# DISPC_VID1 register map
Vendor: Texas Instruments
Peripheral module from a debugger description file (folder DM50x).
Registers are 32-bit, access per field, reset 0x0 unless marked. A register's access mark holds for its fields unless they carry their own. Offsets are as the file gives them; lines under a group give offsets from that group; [hi:lo] are bit positions; {n}, {i} and the like mark numbered series; 'fields as' and 'values as' point back to an identical list; <NAME> marks a mode.

## DISPC_VID1
0x00 DISPC_VID_ACCUH_j_0 — The register configures the resize accumulator init values for horizontal up/down-sampling of the video window (DISPC_VIDx_ACCU__0 DISPC_VIDx_ACCU__1 for ping-pong mechanism with external trigger, based on the field polarity) It is used for ARGB and Y setting. Shadow register.
  [23:0] HORIZONTALACCU rw — Horizontal initialization accu signed value.
0x04 DISPC_VID_ACCUH_j_1 — The register configures the resize accumulator init values for horizontal up/down-sampling of the video window (DISPC_VIDx_ACCU__0 DISPC_VIDx_ACCU__1 for ping-pong mechanism with external trigger, based on the field polarity) It is used for ARGB and Y setting. Shadow register.
  fields as DISPC_VID_ACCUH_j_0
0x08 DISPC_VID_ACCUH2_j_0 — The register configures the resize accumulator init value for horizontal up/down-sampling of the video window (DISPC_VID#n_ACCU2__0 DISPC_VID#n_ACCU2__1 for ping-pong mechanism with external trigger, based on the field polarity) It is used for Cb and Cr setting. It is used only when the pixel format at the input of the filter is one of the YUV formats. If the pixel format at the input of the filter is ARGB (all ARGB, RGB, RGBA are converted to ARGB32-8888 by the color space conversion before going to the filter is the color space conversion is done before the filter). When the register is not used by the HW, any value can be used for the bit-fields. Shadow register.
  [23:0] HORIZONTALACCU rw — Horizontal initialization accu signed value
0x0C DISPC_VID_ACCUH2_j_1 — The register configures the resize accumulator init value for horizontal up/down-sampling of the video window (DISPC_VID#n_ACCU2__0 DISPC_VID#n_ACCU2__1 for ping-pong mechanism with external trigger, based on the field polarity) It is used for Cb and Cr setting. It is used only when the pixel format at the input of the filter is one of the YUV formats. If the pixel format at the input of the filter is ARGB (all ARGB, RGB, RGBA are converted to ARGB32-8888 by the color space conversion before going to the filter is the color space conversion is done before the filter). When the register is not used by the HW, any value can be used for the bit-fields. Shadow register.
  fields as DISPC_VID_ACCUH2_j_0
0x10 DISPC_VID_ACCUV_j_0 — The register configures the resize accumulator init values for horizontal and vertical up/down-sampling of the video window (DISPC_VIDx_ACCU__0 DISPC_VIDx_ACCU__1 for ping-pong mechanism with external trigger, based on the field polarity) It is used for ARGB and Y setting. Shadow register.
  [23:0] VERTICALACCU rw — Vertical initialization accu signed value.
0x14 DISPC_VID_ACCUV_j_1 — The register configures the resize accumulator init values for horizontal and vertical up/down-sampling of the video window (DISPC_VIDx_ACCU__0 DISPC_VIDx_ACCU__1 for ping-pong mechanism with external trigger, based on the field polarity) It is used for ARGB and Y setting. Shadow register.
  [23:0] VERTICALACCU rw — Vertical initialization accu signed value.
0x18 DISPC_VID_ACCUV2_j_0 — The register configures the resize accumulator init value for vertical up/down-sampling of the video window (DISPC_VID1_ACCU2__0 DISPC_VID1_ACCU2__1 for ping-pong mechanism with external trigger, based on the field polarity) It is used for Cb and Cr setting. It is used only when the pixel format at the input of the filter is one of the YUV formats. If the pixel format at the input of the filter is ARGB (all ARGB, RGB, RGBA are converted to ARGB32-8888 by the color space conversion before going to the filter is the color space conversion is done before the filter). When the register is not used by the HW, any value can be used for the bit-fields. Shadow register.
  [23:0] VERTICALACCU rw — Vertical initialization accu signed value.
0x1C DISPC_VID_ACCUV2_j_1 — The register configures the resize accumulator init value for vertical up/down-sampling of the video window (DISPC_VID1_ACCU2__0 DISPC_VID1_ACCU2__1 for ping-pong mechanism with external trigger, based on the field polarity) It is used for Cb and Cr setting. It is used only when the pixel format at the input of the filter is one of the YUV formats. If the pixel format at the input of the filter is ARGB (all ARGB, RGB, RGBA are converted to ARGB32-8888 by the color space conversion before going to the filter is the color space conversion is done before the filter). When the register is not used by the HW, any value can be used for the bit-fields. Shadow register.
  [23:0] VERTICALACCU rw — Vertical initialization accu signed value.
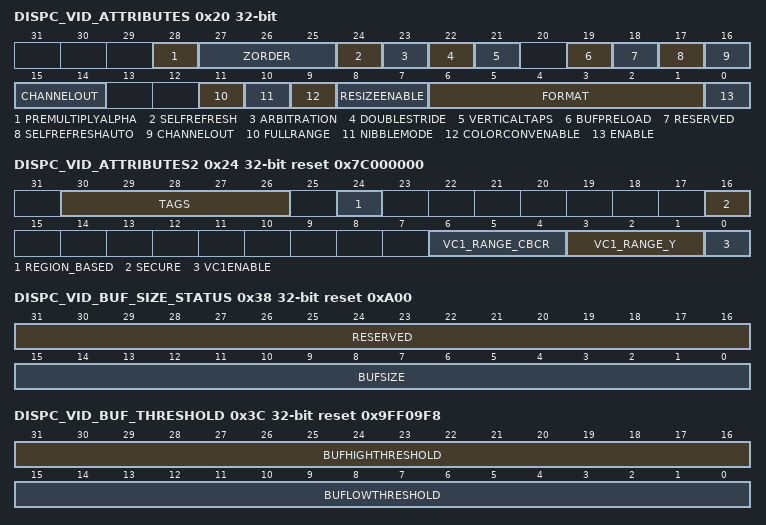
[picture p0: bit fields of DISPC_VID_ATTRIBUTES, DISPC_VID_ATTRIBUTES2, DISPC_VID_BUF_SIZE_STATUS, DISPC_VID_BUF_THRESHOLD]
0x20 DISPC_VID_ATTRIBUTES — The register configures the attributes of the video window. Shadow register.
  [28] PREMULTIPLYALPHA rw — The field configures the DISPC VID1 to process incoming data as premultiplied alpha data or non premultiplied alpha data. Default setting is non premultiplied alpha data.
    0=NONPREMULTIPLIEDALPHA (Non premultiplyalpha data color component); 1=PREMULTIPLIEDALPHA (Premultiplyalpha data color component)
  [27:25] ZORDER rw — Z-Order defining the priority of the layer compared to others when overlaying. It is SW responsibility to ensure that each layer connected to the same overlay manager has a different z-order value.
    1=Z-order 1: layer above layer with z-order value of 0 and below layers with z-order values of 2 and 3; 0=Z-order 0: layer above solid background color and below layer with higher Z-order values; 2=Z-order 2: layer above layers with z-order value of 0 and 1 and below layer with z-order value of 3; 4=Z-order 4: layer above layers with z-order value of 0, 1, 2 and 3 and below layer with z-order value of 5; 5=Z-order 5: layer above all the other layers except cursor; 3=Z-order 3: layer above layers with z-order value of 0, 1 and 2 and below layer with z-order value of 4
  [24] SELFREFRESH rw — Enables the self refresh of the video window from its own DMA buffer only.
    0=SELFREFRESHDIS (The video pipeline accesses the interconnect to fetch data from the system memory.); 1=SELFREFRESHENB (The video pipeline does not need anymore to fetch data from memory. Only the DMA buffer associated with the video1 is used. It takes effect after the frame has been loaded in the DMA buffer.)
  [23] ARBITRATION rw — Determines the priority of the video pipeline. The video pipeline is one of the high priority pipeline. The arbitration gives always the priority first to the high priority pipelines using round-robin between them. When there is only normal priority pipelines sending requests, the round-robin applies between them.
    0=NORMALPRIO (The video pipeline is one of the normal priority pipeline.); 1=HIGHPRIO (The video pipeline is one of the high priority pipeline.)
  [22] DOUBLESTRIDE rw — Determines if the stride for CbCr buffer is the 1x or 2x of the Y buffer stride. It is only used in case of YUV420 and 2D access
    0=INITIAL (The CbCr stride value is equal to the Y stride.); 1=DOUBLE (The CbCr stride value is double to the Y stride.)
  [21] VERTICALTAPS rw — Video Vertical Resize Tap Number. The vertial poly-phase filter can be configured in 3-tap or 5-tap configuration. According to the number of taps, the maximum input picture width is double while using 3-tap compared to 5-tap.
    0=TAPS3 (3 taps are used for the vertical filtering logic. The 2 other taps are not used. The associated bit-fields for the 2 other taps coefficients do not need to be initialized.); 1=TAPS5 (5 taps are used for the vertical filtering logic.)
  [19] BUFPRELOAD rw — Video Preload Value
    0=DEFVAL (H/W prefetches pixels up to the preload value defined in the preload register); 1=HIGHTHRES (H/W prefetches pixels up to high threshold value)
  [18] RESERVED ro — Write 0's for future compatibility. Reads return 0.
  [17] SELFREFRESHAUTO rw — Automatic self refresh mode
    0=SELFREFRESHAUTODIS (The transition from SELFREFRESH <disabled> to <enabled> is controlled by SW.); 1=SELFREFRESHAUTOEN (The transition from SELFREFRESH <disabled> to <enabled> is controlled only by HW.)
  [16:14] CHANNELOUT rw — Video Channel Out configuration wr: immediate
    0=VP1SEL (OVR1 (VP1)); 1=VP1SEL (OVR2); 4=WBSEL
  [11] FULLRANGE rw — Color Space Conversion full range setting.
    0=LIMRANGE (Limited range selected: 16 subtracted from Y before color space conversion); 1=FULLRANGE (Full range selected: Y is not modified before the color space conversion)
  [10] NIBBLEMODE rw — Video Nibble mode (only for 1-, 2- and 4-bpp)
    0=NIBBLEMODEDIS (Nibble mode is disabled); 1=NIBBLEMODEEN (Nibble mode is enabled)
  [9] COLORCONVENABLE rw — Enable the color space conversion. The HW does not enable/disable the conversion based on the pixel format. The bit-field shall be reset when the format is not YUV.
    0=COLSPCDIS (Disable Color Space Conversion YUV to RGB); 1=COLSPCENB (Enable Color Space Conversion YUV to RGB)
  [8:7] RESIZEENABLE rw — Video Resize Enable
    0=RESIZEPROC (Disable both horizontal and vertical resize processing); 1=HRESIZE (Enable the horizontal resize processing); 3=HVRESIZE (Enable both horizontal and vertical resize processing); 2=VRESIZE (Enable the vertical resize processing)
  [6:1] FORMAT rw — Video Format. It defines the pixel format when fetching the video frame buffer.
    9=RGBA32_8888; 21=BITMAP8 (BITMAP8 (CLUT is required)); 8=ABGR32_8888; 5=ARGB16_1555; 46=XRGB32_2101010; 2=RGBA16_4444; 4=BGR16_565; 1=ABGR16_4444; 63=UYVY (UYVY 4:2:2 co-sited); 40=XBGR32_8888; 0=ARGB16_4444; 62=YUV2 (YUV2 4:2:2 co-sited); 11=RGB24P_888 (RGB24-888 (24-bit container)); 61=NV12 (NV12/N21 4:2:0 2 buffers (Y + UV)); 32=XRGB16_4444 (xRGB12-4444); 3=RGB16_565; 23=BGR565A8; 48=XRGB64_16161616; 49=RGBX64_16161616; 17=RGBA64_16161616; 6=ABGR16_1555; 47=XBGR32_2101010; 10=BGRA32_8888; 38=XBGR16_1555; 16=ARGB64_16161616; 33=XBGR16_4444; 37=XRGB16_1555; 18=BITMAP1 (BITMAP1 (CLUT is required)); 19=BITMAP2 (BITMAP2 (CLUT is required)); 20=BITMAP4 (BITMAP4 (CLUT is required)); 14=ARGB32_2101010; 22=RGB565A8; 42=BGRX32_8888; 7=ARGB32_8888; 39=XRGB32_8888 (xRGB32-8888 (32-bit container)); 41=RGBX32_8888 (RGBx32-8888 (24-bit RGB aligned on MSB of the 32-bit container)); 15=ABGR32_2101010; 34=RGBX16_4444
  [0] ENABLE rw — Video pipeline Enable
    0=VIDEODIS (Video disabled (video pipeline inactive and window not present)); 1=VIDEOENB (Video enabled (video pipeline active and window present on the screen))
0x24 DISPC_VID_ATTRIBUTES2 reset 0x7C000000 — The register configures the attributes of the video window. Shadow register.
  [30:26] TAGS rw — Number of OCP TAGS to be used for the pipeline (from 1 to 32)
  [24] REGION_BASED rw — Enable region-based mechanism
    0=DISABLE; 1=ENABLE
  [16] SECURE rw — OCP requests corresponds to pipeline data are secure/unsecure. The bit-field can be modified only by secure transaction using MReqSecure qualifier.
  [6:4] VC1_RANGE_CBCR rw — Defines the VC1 range value for the CbCr component from 0 to 7.
  [3:1] VC1_RANGE_Y rw — Defines the VC1 range value for the Y component from 0 to 7.
  [0] VC1ENABLE rw — Enable/disable the VC1 range mapping processing. The bit-field is ignored if the format is not one of the supported YUV formats.
    0=VC1DIS (VC1 range mapping disabled); 1=VC1ENB (VC1 range mapping enabled)
0x28 DISPC_VID_BA_j_0 rw — The register configures the base address of the video buffer for the video window (DISPC_VID1_BA__0 DISPC_VID1_BA__1 for ping-pong mechanism with external trigger, based on the field polarity otherwise only DISPC_VID1_BA__0 is used). Shadow register.
  [31:0] BA — Video base address When decompression is enabled bit[5:0] shall be set to 0. Base address of the video buffer (aligned on pixel size boundary except in case of RGB24 packed format, 4-pixel alignment is required; in case of YUV422, 2-pixel alignment is required, and YUV420, byte alignment is supported)). It case of YUV 4:2:0 format, it indicates the base address of the Y buffer. When the TILER is addressed, the bits: [28:27] = 0x0 for 8-bit tiled [28:27] = 0x1 for 16-bit tiled [28:27] = 0x2 for 32-bit tiled [28:27] = 0x3 for page mode [31:29] = 0x0 for 0-degree view [31:29] = 0x1 for 180-degree view + mirroring [31:29] = 0x2 for 0-degree view + mirroring [31:29] = 0x3 for 180-degree view [31:29] = 0x4 for 270-degree view + mirroring [31:29] = 0x5 for 270-degree view [31:29] = 0x6 for 90-degree view [31:29] = 0x7 for 90-degree view + mirroring Otherwise the bits indicated the corresponding bit address to access the SDRAM.
0x2C DISPC_VID_BA_j_1 rw — The register configures the base address of the video buffer for the video window (DISPC_VID1_BA__0 DISPC_VID1_BA__1 for ping-pong mechanism with external trigger, based on the field polarity otherwise only DISPC_VID1_BA__0 is used). Shadow register.
  fields as DISPC_VID_BA_j_0
0x30 DISPC_VID_BA_UV_j_0 rw — The register configures the base address of the UV buffer for the video window. (DISPC_VID1_BA_UV__0 DISPC_VID1_BA_UV__1 for ping-pong mechanism with external trigger, based on the field polarity otherwise only DISPC_VID1_BA_UV__0 is used)). The register is also used to configure the RGB plane BA for RGB565A8 format Shadow register.
  [31:0] BA — Video base address alinged on 16-bit boundary Base address of the UV video buffer used only in case of YUV420-NV12 When the TILER is addressed, the bits: [28:27] = 0x0 for 8-bit tiled [28:27] = 0x1 for 16-bit tiled [28:27] = 0x2 for 32-bit tiled [28:27] = 0x3 for page mode [31:29] = 0x0 for 0-degree view [31:29] = 0x1 for 180-degree view + mirroring [31:29] = 0x2 for 0-degree view + mirroring [31:29] = 0x3 for 180-degree view [31:29] = 0x4 for 270-degree view + mirroring [31:29] = 0x5 for 270-degree view [31:29] = 0x6 for 90-degree view [31:29] = 0x7 for 90-degree view + mirroring Otherwise the bits indicated the corresponding bit address to access the SDRAM.
0x34 DISPC_VID_BA_UV_j_1 rw — The register configures the base address of the UV buffer for the video window. (DISPC_VID1_BA_UV__0 DISPC_VID1_BA_UV__1 for ping-pong mechanism with external trigger, based on the field polarity otherwise only DISPC_VID1_BA_UV__0 is used)). The register is also used to configure the RGB plane BA for RGB565A8 format Shadow register.
  fields as DISPC_VID_BA_UV_j_0
0x38 DISPC_VID_BUF_SIZE_STATUS ro reset 0xA00 — The register defines the Video buffer size for the video pipeline.
  [31:16] RESERVED — Write 0's for future compatibility. Reads return 0
  [15:0] BUFSIZE — Video DMA buffer Size in number of 128-bits
0x3C DISPC_VID_BUF_THRESHOLD rw reset 0x9FF09F8 — The register configures the video buffer associated with the video pipeline. Shadow register.
  [31:16] BUFHIGHTHRESHOLD — Video DMA buffer High Threshold Number of 128-bits defining the threshold value.
  [15:0] BUFLOWTHRESHOLD — DMA buffer High Threshold Number of 128-bits defining the threshold value.
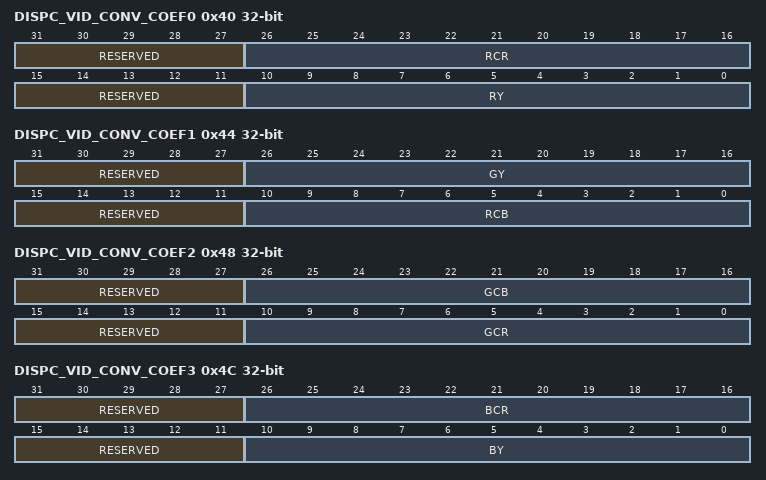
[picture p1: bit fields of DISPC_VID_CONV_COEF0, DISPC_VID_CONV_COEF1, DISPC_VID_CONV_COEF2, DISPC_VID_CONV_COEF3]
0x40 DISPC_VID_CONV_COEF0 — The register configures the color space conversion matrix coefficients for the video pipeline. Shadow register.
  [31:27] RESERVED ro — Write 0's for future compatibility. Reads return 0
  [26:16] RCR rw — RCr Coefficient Encoded signed value (from -1024 to 1023).
  [15:11] RESERVED ro — Write 0's for future compatibility. Reads return 0
  [10:0] RY rw — RY Coefficient Encoded signed value (from -1024 to 1023).
0x44 DISPC_VID_CONV_COEF1 — The register configures the color space conversion matrix coefficients for the video pipeline. Shadow register.
  [31:27] RESERVED ro — Write 0's for future compatibility. Reads return 0
  [26:16] GY rw — GY Coefficient Encoded signed value (from -1024 to 1023).
  [15:11] RESERVED ro — Write 0's for future compatibility. Reads return 0
  [10:0] RCB rw — RCb Coefficient Encoded signed value (from -1024 to 1023).
0x48 DISPC_VID_CONV_COEF2 — The register configures the color space conversion matrix coefficients for the video pipeline. Shadow register.
  [31:27] RESERVED ro — Write 0's for future compatibility. Reads return 0
  [26:16] GCB rw — GCb Coefficient Encoded signed value (from -1024 to 1023).
  [15:11] RESERVED ro — Write 0's for future compatibility. Reads return 0
  [10:0] GCR rw — GCr Coefficient Encoded signed value (from -1024 to 1023).
0x4C DISPC_VID_CONV_COEF3 — The register configures the color space conversion matrix coefficients for the video pipeline. Shadow register.
  [31:27] RESERVED ro — Write 0's for future compatibility. Reads return 0
  [26:16] BCR rw — BCr coefficient Encoded signed value (from -1024 to 1023).
  [15:11] RESERVED ro — Write 0's for future compatibility. Reads return 0
  [10:0] BY rw — BY coefficient Encoded signed value (from -1024 to 1023).
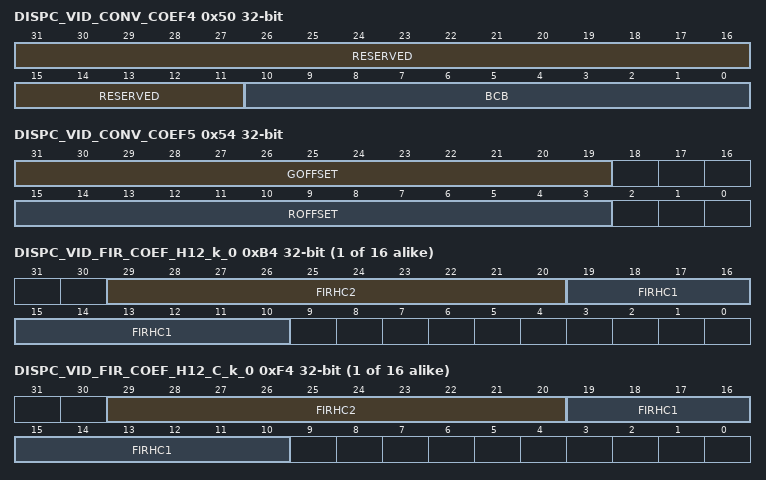
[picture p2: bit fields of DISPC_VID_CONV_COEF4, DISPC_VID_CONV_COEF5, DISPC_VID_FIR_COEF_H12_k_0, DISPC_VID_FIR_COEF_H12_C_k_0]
0x50 DISPC_VID_CONV_COEF4 — The register configures the color space conversion matrix coefficients for the video pipeline. Shadow register.
  [31:11] RESERVED ro — Write 0's for future compatibility. Reads return 0
  [10:0] BCB rw — BCb Coefficient Encoded signed value (from -1024 to 1023).
0x54 DISPC_VID_CONV_COEF5 — The register configures the color space conversion matrix coefficients for the video pipeline. Shadow register.
  [31:19] GOFFSET rw — G offset Encoded signed value (from -4096 to 4095).
  [15:3] ROFFSET rw — R offset Encoded signed value (from -4096 to 4095).
0x58 DISPC_VID_CONV_COEF6 — The register configures the color space conversion matrix coefficients for the video pipeline. Shadow register.
  [15:3] BOFFSET rw — B offset Encoded signed value (from -4096 to 4095).
0x5C DISPC_VID_FIRH reset 0x200000 — The register configures the resize factor for horizontal up/down-sampling of the video window. It is used for ARGB and Y setting. Shadow register.
  [23:0] FIRHINC rw — Horizontal increment of the up/down-sampling filter. The value 0 is invalid.
0x60 DISPC_VID_FIRH2 reset 0x200000 — The register configures the resize factor for horizontal up/down-sampling of the video window. It is used for Crb and Cr setting. It is used only when the pixel format at the input of the filter is one of the YUV formats. If the pixel format at the input of the filter is ARGB (all ARGB, RGB, RGBA are converted to ARGB32-8888 by the color space conversion before going to the filter is the color space conversion is done before the filter). When the register is not used by the HW, any value can be used for the bit-fields. Shadow register.
  [23:0] FIRHINC rw — Horizontal increment of the up/down-sampling filter for Cb and Cr. The value 0 is invalid.
0x64 DISPC_VID_FIRV reset 0x200000 — The register configures the resize factor for vertical up/down-sampling of the video window. It is used for ARGB and Y setting. Shadow register.
  [23:0] FIRVINC rw — Vertical increment of the up/down-sampling filter. The value 0 is invalid.
0x68 DISPC_VID_FIRV2 reset 0x200000 — The register configures the resize factor for vertical up/down-sampling of the video window. It is used for Crb and Cr setting. It is used only when the pixel format at the input of the filter is one of the YUV formats. If the pixel format at the input of the filter is ARGB (all ARGB, RGB, RGBA are converted to ARGB32-8888 by the color space conversion before going to the filter is the color space conversion is done before the filter). When the register is not used by the HW, any value can be used for the bit-fields. Shadow register.
  [23:0] FIRVINC rw — Vertical increment of the up/down-sampling filter for Cb and Cr. The value 0 is invalid.
{0x6C+4i} DISPC_VID_FIR_COEF_H0_i_{i} (i=0..8) — The bank of registers configure the up/down-scaling coefficients for the horizontal resize of the video picture associated with the video window for the 16 phases It is used for ARGB and Y setting. Shadow register.
  [9:0] FIRHC0 rw — Unsigned coefficient C0 for the horizontal up/down-scaling with the phase n
{0x90+4i} DISPC_VID_FIR_COEF_H0_C_i_{i} (i=0..8) — The bank of registers configure the up/down-scaling coefficients for the horizontal resize of the video picture associated with the video window for the phases from 0 to 15. It is used for Crb and Cr setting. It is used only when the pixel format at the input of the filter is one of the YUV formats. If the pixel format at the input of the filter is ARGB (all ARGB, RGB, RGBA are converted to ARGB32-8888 by the color space conversion before going to the filter is the color space conversion is done before the filter). When the register is not used by the HW, any value can be used for the bit-fields. Shadow register.
  fields as DISPC_VID_FIR_COEF_H0_i_0
{0xB4+4i} DISPC_VID_FIR_COEF_H12_k_{i} (i=0..15) — The bank of registers configure the up/down-scaling coefficients for the horizontal resize of the video picture associated with the video window for the 16 phases It is used for ARGB and Y setting. Shadow register.
  [29:20] FIRHC2 rw — Signed coefficient C2 for the horizontal up/down-scaling with the phase n
  [19:10] FIRHC1 rw — Signed coefficient C1 for the horizontal up/down-scaling with the phase n
{0xF4+4i} DISPC_VID_FIR_COEF_H12_C_k_{i} (i=0..15) — The bank of registers configure the up/down-scaling coefficients for the horizontal resize of the video picture associated with the video window for the phases from 0 to 15. It is used for Crb and Cr setting. It is used only when the pixel format at the input of the filter is one of the YUV formats. If the pixel format at the input of the filter is ARGB (all ARGB, RGB, RGBA are converted to ARGB32-8888 by the color space conversion before going to the filter is the color space conversion is done before the filter). When the register is not used by the HW, any value can be used for the bit-fields. Shadow register.
  fields as DISPC_VID_FIR_COEF_H12_k_0
{0x134+4i} DISPC_VID_FIR_COEF_V0_i_{i} (i=0..8) — The bank of registers configure the up/down-scaling coefficients for the vertical resize of the video picture associated with the video window for the 16 phases It is used for ARGB and Y setting. Shadow register.
  [9:0] FIRVC0 rw — Unsigned coefficient C0 for the vertical up/down-scaling with the phase n
{0x158+4i} DISPC_VID_FIR_COEF_V0_C_i_{i} (i=0..8) — The bank of registers configure the up/down-scaling coefficients for the vertical resize of the video picture associated with the video window for the phases from 0 to 15. It is used for Crb and Cr setting. It is used only when the pixel format at the input of the filter is one of the YUV formats. If the pixel format at the input of the filter is ARGB (all ARGB, RGB, RGBA are converted to ARGB32-8888 by the color space conversion before going to the filter is the color space conversion is done before the filter). When the register is not used by the HW, any value can be used for the bit-fields. Shadow register.
  fields as DISPC_VID_FIR_COEF_V0_i_0
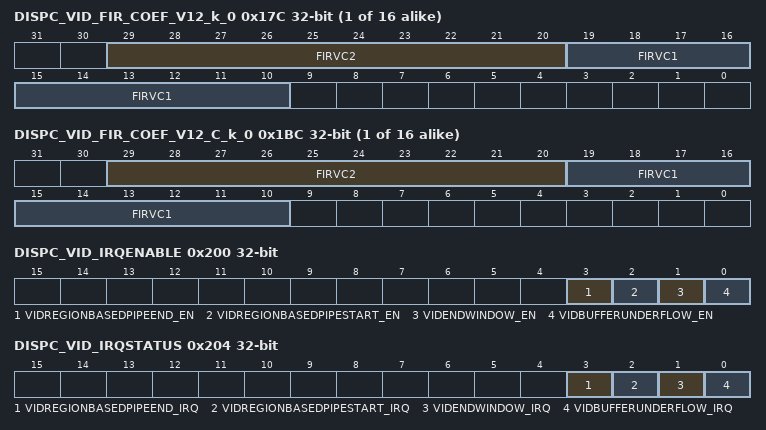
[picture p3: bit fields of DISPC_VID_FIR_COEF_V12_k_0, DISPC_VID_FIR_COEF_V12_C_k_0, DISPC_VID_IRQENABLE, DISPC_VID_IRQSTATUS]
{0x17C+4i} DISPC_VID_FIR_COEF_V12_k_{i} (i=0..15) — The bank of registers configure the up/down-scaling coefficients for the vertical resize of the video picture associated with the video window for the 16 phases It is used for ARGB and Y setting. Shadow register.
  [29:20] FIRVC2 rw — Signed coefficient C2 for the vertical up/down-scaling with the phase n
  [19:10] FIRVC1 rw — Signed coefficient C1 for the vertical up/down-scaling with the phase n
{0x1BC+4i} DISPC_VID_FIR_COEF_V12_C_k_{i} (i=0..15) — The bank of registers configure the up/down-scaling coefficients for the vertical resize of the video picture associated with the video window for the phases from 0 to 15. It is used for Crb and Cr setting. It is used only when the pixel format at the input of the filter is one of the YUV formats. If the pixel format at the input of the filter is ARGB (all ARGB, RGB, RGBA are converted to ARGB32-8888 by the color space conversion before going to the filter is the color space conversion is done before the filter). When the register is not used by the HW, any value can be used for the bit-fields. Shadow register.
  fields as DISPC_VID_FIR_COEF_V12_k_0
0x1FC DISPC_VID_GLOBAL_ALPHA reset 0xFF — The register defines the global alpha value for the video pipeline. Shadow register.
  [7:0] GLOBALALPHA rw — Global alpha value from 0 to 255. 0 corresponds to fully transparent and 255 to fully opaque.
0x200 DISPC_VID_IRQENABLE — This register allows to mask/unmask the module internal sources of interrupt, on an event-by-event basis
  [3] VIDREGIONBASEDPIPEEND_EN rw — PIPE end window IRQ for region-based feature
    0=MASKED (VIDREGIONBASEDPIPEEND is masked); 1=GENINT (VIDREGIONBASEDPIPEEND generates an interrupt when it occurs)
  [2] VIDREGIONBASEDPIPESTART_EN rw — PIPE start window IRQ for region-based feature
    0=MASKED (VIDREGIONBASEDPIPESTART is masked); 1=GENINT (VIDREGIONBASEDPIPESTART generates an interrupt when it occurs)
  [1] VIDENDWINDOW_EN rw — The end of the video Window has been reached. It is detected by the overlay manager when the full video has been displayed.
    0=MASKED (EndVid1Window is masked); 1=GENINT (EndVid1Window generates an interrupt when it occurs)
  [0] VIDBUFFERUNDERFLOW_EN rw — Video DMA Buffer Underflow. The DMA buffer is not necessary empty but required data are not present in the DMA buffer (due to out of order responses)
    0=MASKED (Vid1BufferUnderflow is masked); 1=GENINT (Vid1BufferUnderflow generates an interrupt when it occurs)
0x204 DISPC_VID_IRQSTATUS — This register regroups all the status of the module internal events that generate an interrupt. Write 1 to a given bit resets this bit
  [all] fields
    0=FALSE (READS: Event is false. WRITES: Status bit unchanged.); 1=TRUE (READS: Event is true (pending). WRITES: Status bit is reset.)
  [3] VIDREGIONBASEDPIPEEND_IRQ rw — PIPE end window IRQ for region-based feature
  [2] VIDREGIONBASEDPIPESTART_IRQ rw — PIPE start window IRQ for region-based feature
  [1] VIDENDWINDOW_IRQ rw — The end of the video Window has been reached. It is detected by the overlay manager when the full video has been displayed.
  [0] VIDBUFFERUNDERFLOW_IRQ rw — Video DMA Buffer Underflow. The DMA buffer is not necessarly empty but required data are not present in the DMA buffer (due to out of order responses)
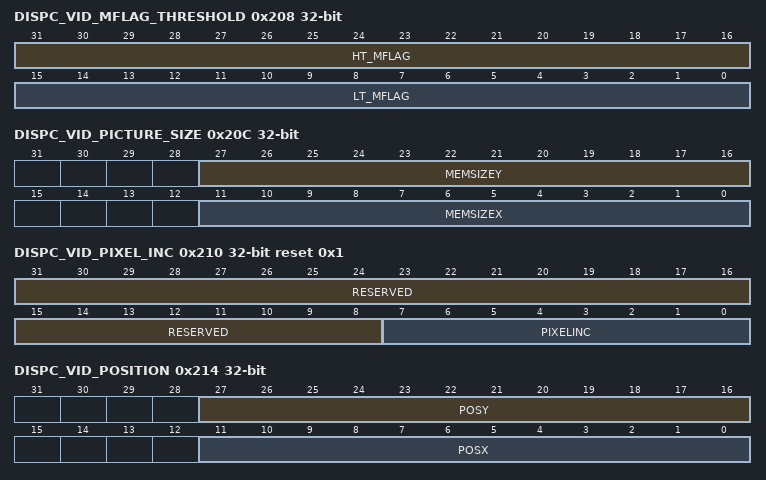
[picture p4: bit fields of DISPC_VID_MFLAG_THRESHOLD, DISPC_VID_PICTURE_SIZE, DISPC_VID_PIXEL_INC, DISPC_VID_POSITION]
0x208 DISPC_VID_MFLAG_THRESHOLD rw — MFLAG thresholds for video pipelines. Shadow register.
  [31:16] HT_MFLAG — High Thresholds (in 128bits) for MFLAG generation: when FIFO fullness reaches HT_MFLAG level, MFLAG is reset to 0
  [15:0] LT_MFLAG — Low Thresholds (in 128bits) for MFLAG generation: when FIFO fullness reaches LT_MFLAG level, MFLAG is set to 1
0x20C DISPC_VID_PICTURE_SIZE — The register configures the size of the video picture associated with the video layer before up/down-scaling. Shadow register.
  [27:16] MEMSIZEY rw — Number of lines of the video picture Encoded value (from 1 to 4096) to specify the number of lines of the video picture in memory (program to value minus one). When predecimation is set, the value represents the size of the image after predecimation but the max size of the unpredecimated image size in memory is still bounded to 2exp(11).
  [11:0] MEMSIZEX rw — Number of pixels of the video picture Encoded value (from 1 to 4096) to specify the number of pixels of the video picture in memory (program to value minus one). The size is limited to the size of the line buffer of the vertical sampling block in case the video picture is processed by the vertical filtering unit. (program to value minus one). When predecimation is set, the value represents the size of the image after predecimation but the max size of the unpredecimated image size in memory is still bounded to 2exp(11).
0x210 DISPC_VID_PIXEL_INC reset 0x1 — The register configures the number of bytes to increment between two pixels for the buffer associated with the video window. The register is used only when the TILER is not present in the system in order to perform low performance rotation. When the TILER IP is present it is highly recommanded to use it for performing the rotation. Shadow register.
  [31:8] RESERVED ro — Write 0's for future compatibility. Reads return 0
  [7:0] PIXELINC rw — Number of bytes to increment between two pixels. Encoded unsigned value (from 1 to 255) to specify the number of bytes between two pixels in the video buffer. The value 0 is invalid. The value 1 means next pixel. The value 1+n*bpp means increment of n pixels. For YUV420, Max supported value is 128.
0x214 DISPC_VID_POSITION — The register configures the position of the video window. Shadow register.
  [27:16] POSY rw — Y position of the video window Encoded value (from 0 to 4095) to specify the Y position of the video window #1 .The line at the top has the Y-position 0.
  [11:0] POSX rw — X position of the video window Encoded value (from 0 to 4095) to specify the X position of the video window #1. The first pixel on the left of the display screen has the X-position 0.
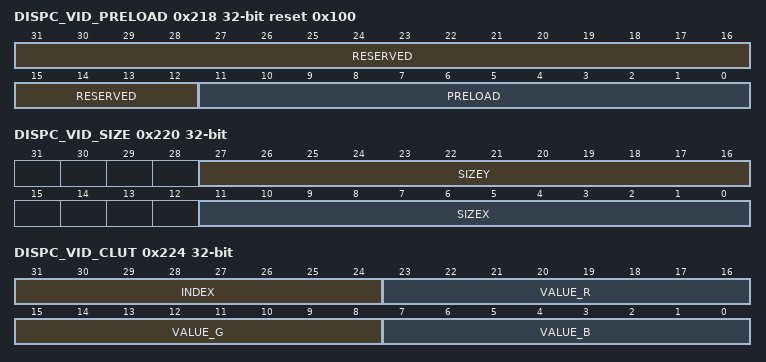
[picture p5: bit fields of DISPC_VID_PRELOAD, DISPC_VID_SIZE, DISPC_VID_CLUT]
0x218 DISPC_VID_PRELOAD reset 0x100 — The register configures the DMA buffer of the video pipeline. Shadow register.
  [31:12] RESERVED ro — Write 0's for future compatibility. Reads return 0
  [11:0] PRELOAD rw — DMA buffer preload value Number of 128-bit words defining the preload value.
0x21C DISPC_VID_ROW_INC rw reset 0x1 — The register configures the number of bytes to increment at the end of the row for the buffer associated with the video window. Shadow register.
  [31:0] ROWINC — Number of bytes to increment at the end of the row Encoded signed value (from -2^31-1 to 2^31) to specify the number of bytes to increment at the end of the row in the video buffer. The value 0 is invalid. The value 1 means next pixel. The value 1+n*bpp means increment of n pixels. The value 1- (n+1)*bpp means decrement of n pixels.
0x220 DISPC_VID_SIZE — The register configures the size of the video window. Shadow register.
  [27:16] SIZEY rw — Number of lines of the video window. Encoded value (from 1 to 4096) to specify the number of lines of the video window (program size -1).
  [11:0] SIZEX rw — Number of pixels of the video window. Encoded value (from 1 to 4096) to specify the number of pixels of the video window (program size -1).
0x224 DISPC_VID_CLUT wo — The register configures the Color Look Up Table (CLUT) for VID pipeline. CLUT is used in conjunction with bitmap formats
  [31:24] INDEX — Defines the location in the table where the bit-field VALUE is stored
  [23:16] VALUE_R — 8-bit value used to defined the value to store at the location in the table defined by the bit-field INDEX.
  [15:8] VALUE_G — 8-bit value used to defined the value to store at the location in the table defined by the bit-field INDEX.
  [7:0] VALUE_B — 8-bit value used to defined the value to store at the location in the table defined by the bit-field INDEX.
